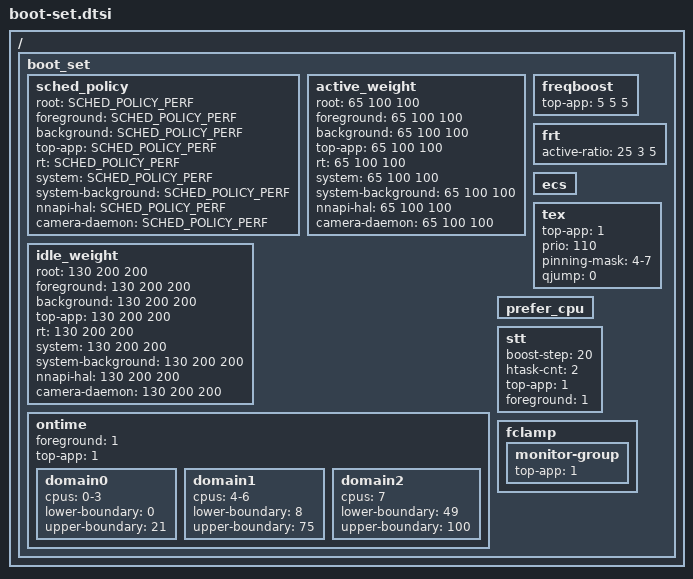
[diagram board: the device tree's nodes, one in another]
/ {
	/* booting exclusive set */
	boot_set: boot_set {
		/* schedudling policy */
		sched_policy {
			root			= <SCHED_POLICY_PERF>;
			foreground 		= <SCHED_POLICY_PERF>;
			background		= <SCHED_POLICY_PERF>;
			top-app			= <SCHED_POLICY_PERF>;
			rt			= <SCHED_POLICY_PERF>;
			system			= <SCHED_POLICY_PERF>;
			system-background	= <SCHED_POLICY_PERF>;
			nnapi-hal		= <SCHED_POLICY_PERF>;
			camera-daemon		= <SCHED_POLICY_PERF>;
		};

		/* weight (%) applied to active cpu's efficiency */
		active_weight {			/* LIT MED BIG */
			root            	= < 65 100 100>;
			foreground      	= < 65 100 100>;
			background      	= < 65 100 100>;
			top-app         	= < 65 100 100>;
			rt			= < 65 100 100>;
			system			= < 65 100 100>;
			system-background	= < 65 100 100>;
			nnapi-hal		= < 65 100 100>;
			camera-daemon		= < 65 100 100>;
		};

		/* weight (%) applied to idle cpu's efficiency */
		idle_weight {	   		/* LIT  MED  BIG */
			root            	= <130 200 200>;
			foreground      	= <130 200 200>;
			background      	= <130 200 200>;
			top-app         	= <130 200 200>;
			rt			= <130 200 200>;
			system			= <130 200 200>;
			system-background	= <130 200 200>;
			nnapi-hal		= <130 200 200>;
			camera-daemon		= <130 200 200>;
		};

		/* Boosting margin applied to frequency selection */
		freqboost {			/* LIT MED BIG */
			top-app			= <  5   5   5>;
		};

		frt {	   			/* LIT MED BIG */
			active-ratio 		= < 25   3   5>;
		};

		/* Ontime Migration */
		ontime {
			foreground 	= <1>;
			top-app		= <1>;

			domain0 {
				cpus = "0-3";
				lower-boundary = <0>;
				upper-boundary = <21>;
			};
			domain1 {
				cpus = "4-6";
				lower-boundary = <8>;
				upper-boundary = <75>;
			};
			domain2 {
				cpus = "7";
				lower-boundary = <49>;
				upper-boundary = <100>;
			};
		};

		ecs { };

		tex {
			top-app		= <1>;
			prio		= <110>;

			pinning-mask	= "4-7";
			qjump		= <0>;
		};

		prefer_cpu {};

		stt {
			boost-step		= <20>;
			htask-cnt		= <2>;
			top-app			= <1>;
			foreground		= <1>;
		};

		fclamp {
			monitor-group {
				top-app         = <1>;
			};
		};
	};
};
